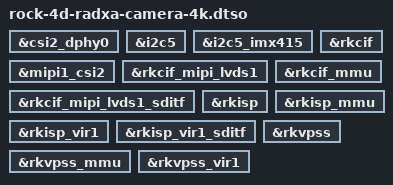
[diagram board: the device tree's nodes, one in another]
/dts-v1/;
/plugin/;
/ {
	fragment@0 {
		target = <&csi2_dphy0>;
		__overlay__ {
			status = "okay";
		};
	};

	fragment@1 {
		target = <&i2c5>;
		__overlay__ {
			status = "okay";
		};
	};

	fragment@2 {
		target = <&i2c5_imx415>;
		__overlay__ {
			status = "okay";
		};
	};

	fragment@3 {
		target = <&mipi1_csi2>;
		__overlay__ {
	
			status = "okay";
		};
	};

	fragment@4 {
		target = <&rkcif>;
		__overlay__ {
			status = "okay";
		};
	};

	fragment@5 {
		target = <&rkcif_mipi_lvds1>;
		__overlay__ {
			status = "okay";
		};
	};

	fragment@6 {
		target = <&rkcif_mipi_lvds1_sditf>;
		__overlay__ {
			status = "okay";
		};
	};

	fragment@7 {
		target = <&rkcif_mmu>;
		__overlay__ {
			status = "okay";
		};
	};

	fragment@8 {
		target = <&rkisp>;
		__overlay__ {
			status = "okay";
		};
	};

	fragment@9 {
		target = <&rkisp_mmu>;
		__overlay__ {
			status = "okay";
		};
	};

	fragment@10 {
		target = <&rkisp_vir1>;
		__overlay__ {
			status = "okay";
		};
	};

	fragment@11 {
		target = <&rkisp_vir1_sditf>;
		__overlay__ {
			status = "okay";
		};
	};
	
	fragment@12 {
		target = <&rkvpss>;
		__overlay__ {
			status = "okay";
		};
	};
	
	fragment@13 {
		target = <&rkvpss_mmu>;
		__overlay__ {
			status = "okay";
		};
	};
	
	fragment@14 {
		target = <&rkvpss_vir1>;
		__overlay__ {
			status = "okay";
		};
	};
};
